# STM32WL5x_CM4 register map
File version: 1.9
CPU: CM4 r0p1, little endian, MPU, FPU, 4 interrupt priority bits
Registers are 32-bit, read-write, reset 0x0 unless marked. A register's access mark holds for its fields unless they carry their own. Offsets are from the block's base; [hi:lo] are bit positions; {n}, {i} and the like mark numbered series; 'fields as' and 'values as' point back to an identical list.

## DBGMCU — Microcontroller Debug Unit
Base 0xE0042000
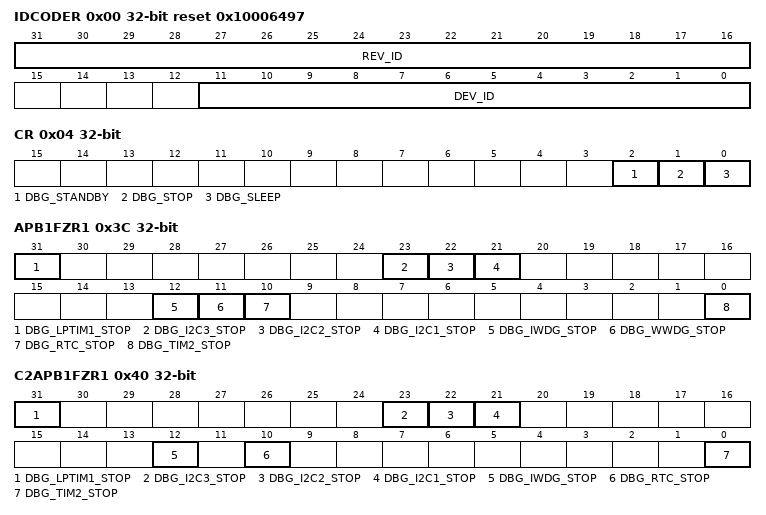
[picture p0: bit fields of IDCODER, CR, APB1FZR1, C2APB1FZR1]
0x00 IDCODER ro reset 0x10006497 — DBGMCU Identity Code Register
  [31:16] REV_ID — Revision
  [11:0] DEV_ID — Device ID
0x04 CR — DBGMCU Configuration Register
  [2] DBG_STANDBY — Allow debug in STANDBY mode
  [1] DBG_STOP — Allow debug in STOP mode
  [0] DBG_SLEEP — Allow debug in SLEEP mode
0x3C APB1FZR1 — DBGMCU CPU1 APB1 Peripheral Freeze Register 1
  [31] DBG_LPTIM1_STOP — LPTIM1 stop in CPU1 debug
  [23] DBG_I2C3_STOP — I2C3 SMBUS timeout stop in CPU1 debug
  [22] DBG_I2C2_STOP — I2C2 SMBUS timeout stop in CPU1 debug
  [21] DBG_I2C1_STOP — I2C1 SMBUS timeout stop in CPU1 debug
  [12] DBG_IWDG_STOP — IWDG stop in CPU1 debug
  [11] DBG_WWDG_STOP — WWDG stop in CPU1 debug
  [10] DBG_RTC_STOP — RTC stop in CPU1 debug
  [0] DBG_TIM2_STOP — TIM2 stop in CPU1 debug
0x40 C2APB1FZR1 — DBGMCU CPU2 APB1 Peripheral Freeze Register 1 [dual core device
  [31] DBG_LPTIM1_STOP, [23] DBG_I2C3_STOP, [22] DBG_I2C2_STOP, [21] DBG_I2C1_STOP, [12] DBG_IWDG_STOP, [10] DBG_RTC_STOP, [0] DBG_TIM2_STOP
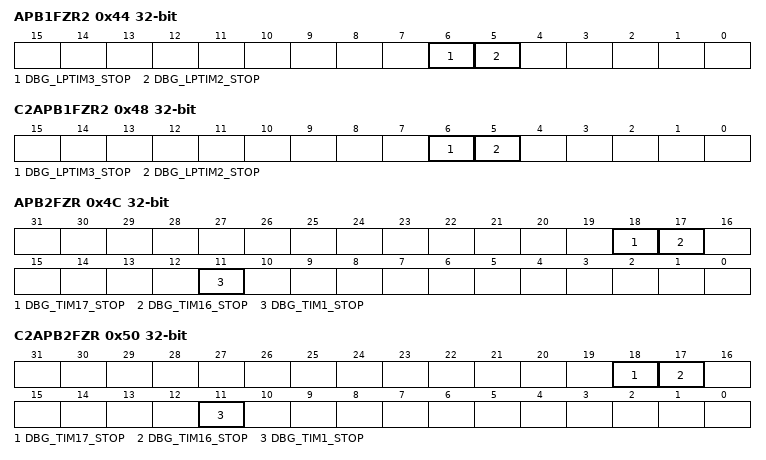
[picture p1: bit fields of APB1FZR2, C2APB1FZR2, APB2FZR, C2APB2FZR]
0x44 APB1FZR2 — DBGMCU CPU1 APB1 Peripheral Freeze Register 2
  [6] DBG_LPTIM3_STOP, [5] DBG_LPTIM2_STOP
0x48 C2APB1FZR2 — DBGMCU CPU2 APB1 Peripheral Freeze Register 2 [dual core device
  [6] DBG_LPTIM3_STOP, [5] DBG_LPTIM2_STOP
0x4C APB2FZR — DBGMCU CPU1 APB2 Peripheral Freeze Register
  [18] DBG_TIM17_STOP, [17] DBG_TIM16_STOP, [11] DBG_TIM1_STOP
0x50 C2APB2FZR — DBGMCU CPU2 APB2 Peripheral Freeze Register [dual core device
  [18] DBG_TIM17_STOP, [17] DBG_TIM16_STOP, [11] DBG_TIM1_STOP

## DMA1 — Direct memory access controller
Base 0x40020000
Same registers: DMA2 0x40020400
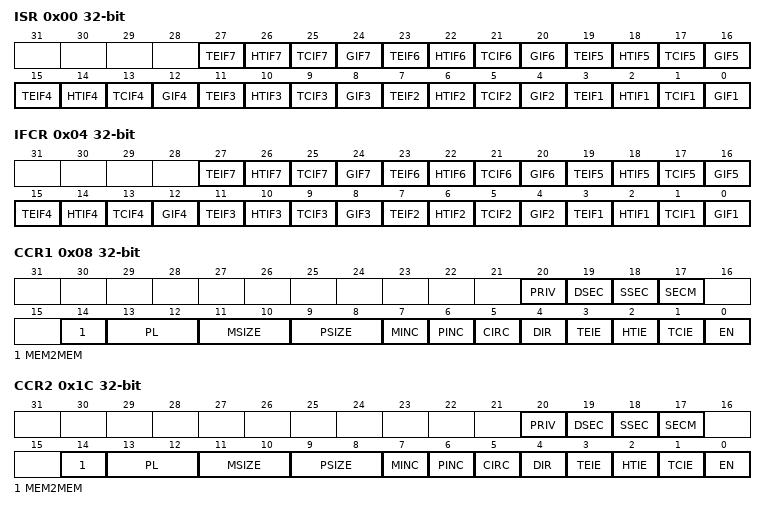
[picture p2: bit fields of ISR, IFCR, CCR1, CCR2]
0x00 ISR ro — interrupt status register
  [4n-1] TEIF{n} (n=1..7) — transfer error (TE) flag for channel {n}
  [4n-2] HTIF{n} (n=1..7) — half transfer (HT) flag for channel {n}
  [4n-3] TCIF{n} (n=1..7) — transfer complete (TC) flag for channel {n}
  [4n-4] GIF{n} (n=1..7) — global interrupt flag for channel {n}
0x04 IFCR wo — interrupt flag clear register
  [4n-1] TEIF{n} (n=1..7) — transfer error flag clear for channel {n}
  [4n-2] HTIF{n} (n=1..7) — half transfer flag clear for channel {n}
  [4n-3] TCIF{n} (n=1..7) — transfer complete flag clear for channel {n}
  [4n-4] GIF{n} (n=1..7) — global interrupt flag clear for channel {n}
0x08 CCR1 — channel x configuration register
  [20] PRIV — rivileged mode
  [19] DSEC — ecurity of the DMA transfer to the destination
  [18] SSEC — ecurity of the DMA transfer from the source
  [17] SECM — ecure mode
  [14] MEM2MEM — memory-to-memory mode
  [13:12] PL — priority level
  [11:10] MSIZE — memory size
  [9:8] PSIZE — peripheral size
  [7] MINC — memory increment mode
  [6] PINC — peripheral increment mode
  [5] CIRC — circular mode
  [4] DIR — data transfer direction
  [3] TEIE — transfer error interrupt enable
  [2] HTIE — half transfer interrupt enable
  [1] TCIE — transfer complete interrupt enable
  [0] EN — channel enable
0x0C CNDTR1 — channel x number of data to transfer register
  [17:0] NDT — number of data to transfer (0 to 218 - 1)
0x10 CPAR1 — channel x peripheral address register
  [31:0] PA — peripheral address
{0x0+0x14*i} CMAR{i} (i=1..7) — channel x memory address register
  [31:0] MA — peripheral address
0x1C CCR2 — channel x configuration register
  fields as CCR1
0x20 CNDTR2 — channel x number of data to transfer register
  [17:0] NDT — number of data to transfer (0 to 218 - 1)
0x24 CPAR2 — channel x peripheral address register
  [31:0] PA — peripheral address
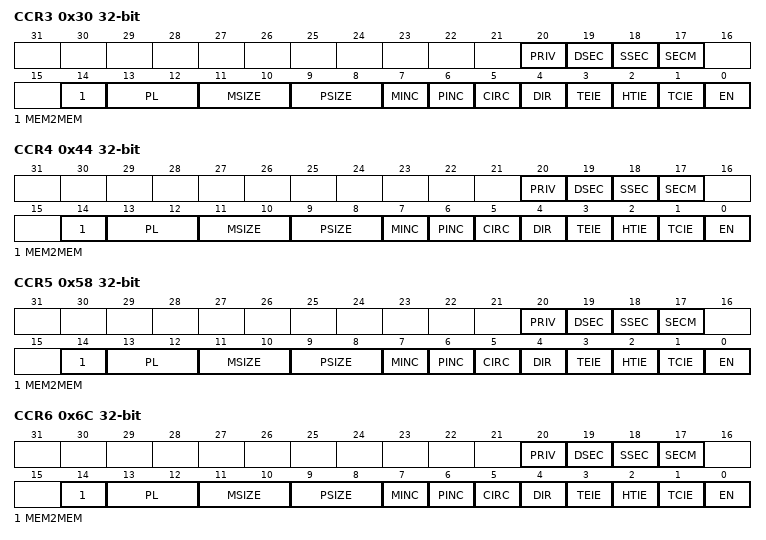
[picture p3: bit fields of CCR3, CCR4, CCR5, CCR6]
0x30 CCR3 — channel x configuration register
  fields as CCR1
0x34 CNDTR3 — channel x number of data to transfer register
  [17:0] NDT — number of data to transfer (0 to 218 - 1)
0x38 CPAR3 — channel x peripheral address register
  [31:0] PA — peripheral address
0x44 CCR4 — channel x configuration register
  fields as CCR1
0x48 CNDTR4 — channel x number of data to transfer register
  [17:0] NDT — number of data to transfer (0 to 218 - 1)
0x4C CPAR4 — channel x peripheral address register
  [31:0] PA — peripheral address
0x58 CCR5 — channel x configuration register
  fields as CCR1
0x5C CNDTR5 — channel x number of data to transfer register
  [17:0] NDT — number of data to transfer (0 to 218 - 1)
0x60 CPAR5 — channel x peripheral address register
  [31:0] PA — peripheral address
0x6C CCR6 — channel x configuration register
  fields as CCR1
0x70 CNDTR6 — channel x number of data to transfer register
  [17:0] NDT — number of data to transfer (0 to 218 - 1)
0x74 CPAR6 — channel x peripheral address register
  [31:0] PA — peripheral address
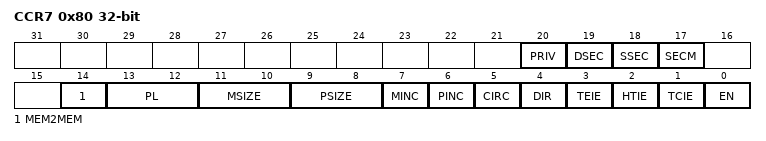
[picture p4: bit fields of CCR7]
0x80 CCR7 — channel x configuration register
  fields as CCR1
0x84 CNDTR7 — channel x number of data to transfer register
  [17:0] NDT — number of data to transfer (0 to 218 - 1)
0x88 CPAR7 — channel x peripheral address register
  [31:0] PA — peripheral address
